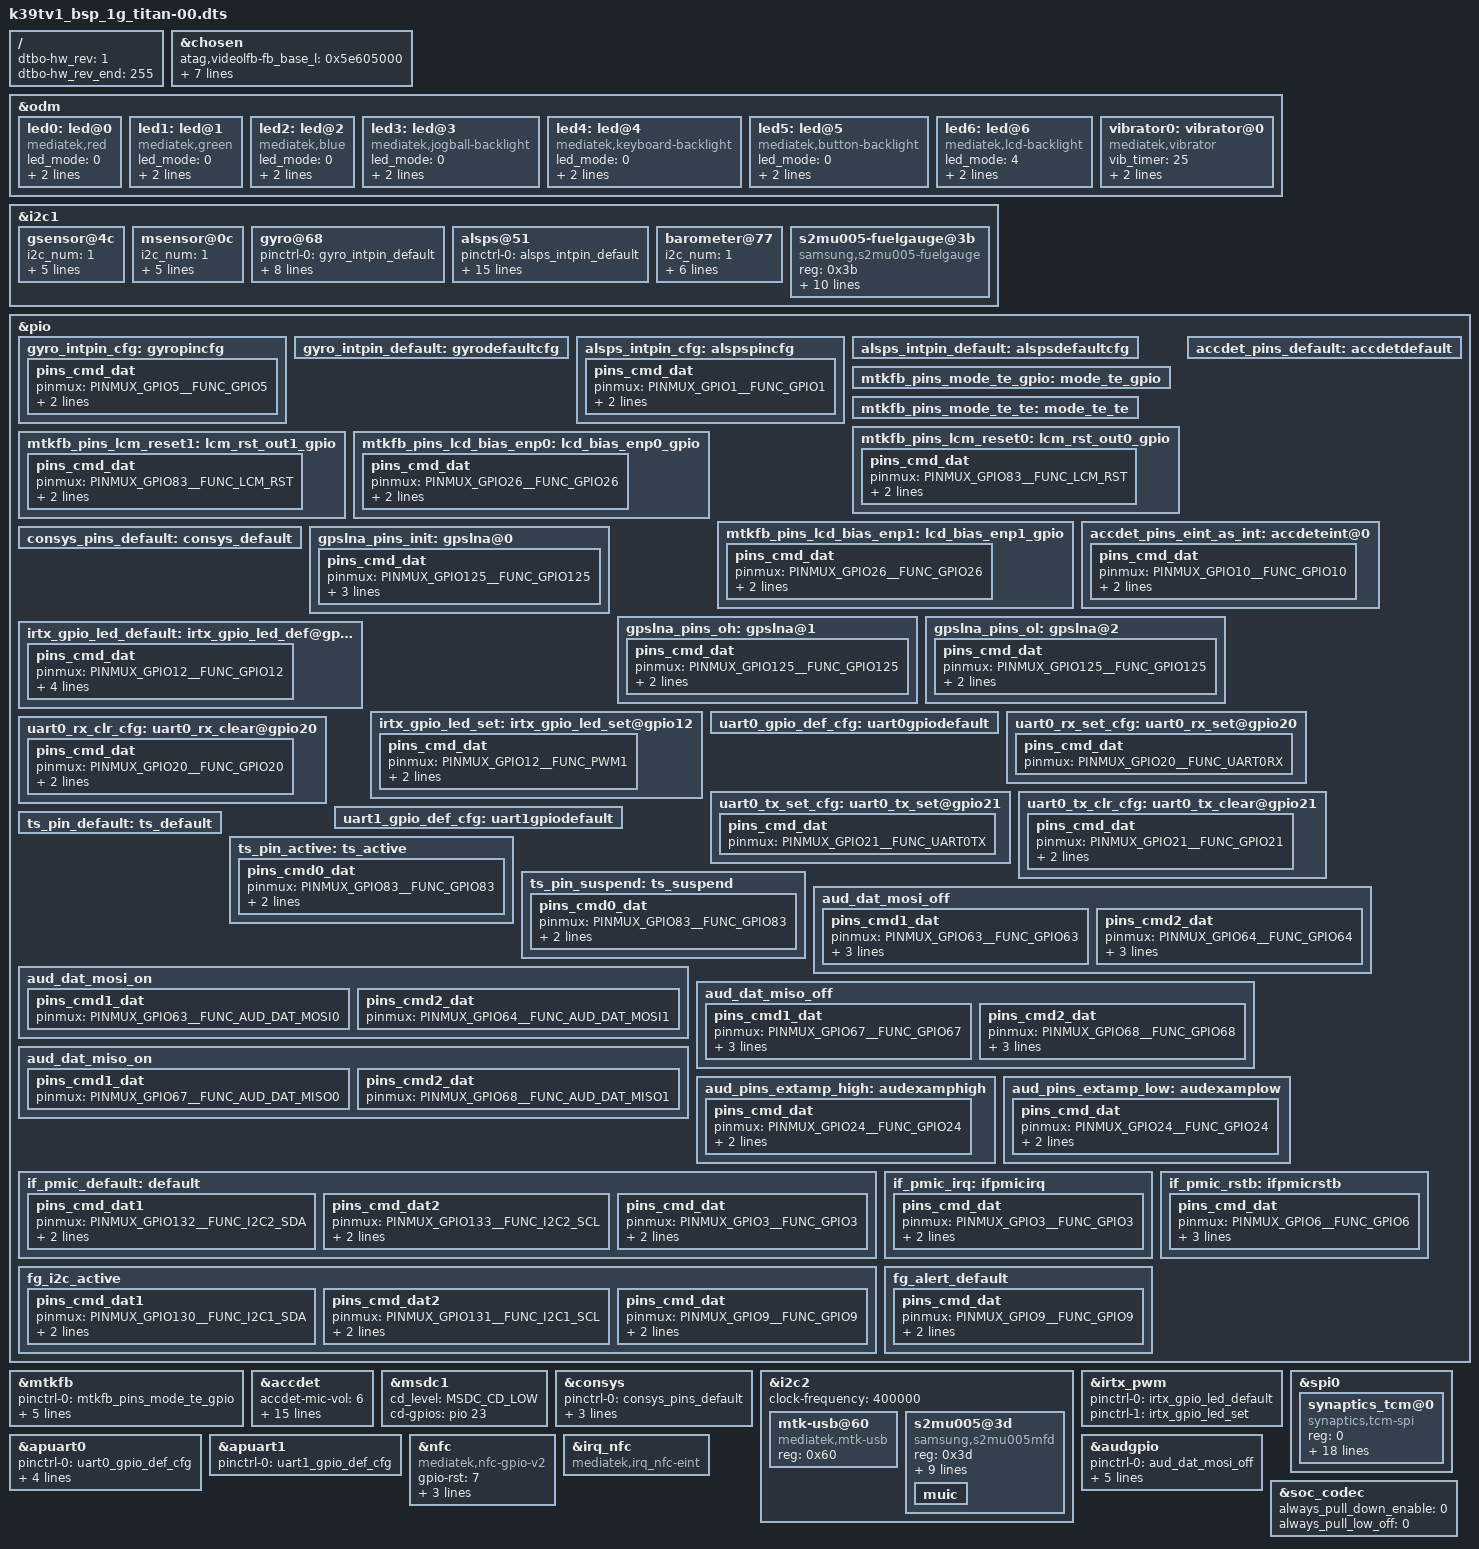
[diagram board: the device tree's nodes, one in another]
/*
 * Mediatek's MT6739 SoC device tree source
 *
 * Copyright (C) 2016 MediaTek Inc.
 *
 * This program is free software; you can redistribute it and/or modify
 * it under the terms of the GNU General Public License version 2 as
 * published by the Free Software Foundation.
 *
 * This program is distributed in the hope that it will be useful,
 * but WITHOUT ANY WARRANTY; without even the implied warranty of
 * MERCHANTABILITY or FITNESS FOR A PARTICULAR PURPOSE.
 * See http://www.gnu.org/licenses/gpl-2.0.html for more details.
 */
#include <generated/autoconf.h>
/dts-v1/;

/plugin/;
#include <dt-bindings/mmc/mt6739-msdc.h>
#include <dt-bindings/pinctrl/mt6739-pinfunc.h>

/ {
	fragment@model {
	target-path = "/";
		__overlay__ {
			dtbo-hw_rev = <1>;
			dtbo-hw_rev_end = <255>;
		};
	};
};

/* chosen */
&chosen {
	/* fpga may has no lk, we need to specify display info here */
	/* fb buffer is reserved using this dts by memory node above */

	atag,videolfb-fb_base_l = <0x5e605000>;
	atag,videolfb-fb_base_h = <0>;
	atag,videolfb-islcmfound = <1>;
	atag,videolfb-islcm_inited = <0>;
	atag,videolfb-fps= <6000>;
	atag,videolfb-vramSize= <0x017bb000>;
	atag,videolfb-lcmname= "nt35521_hd_dsi_vdo_truly_nt50358_drv";
};

&odm {
	led0:led@0 {
		compatible = "mediatek,red";
		led_mode = <0>;
		data = <1>;
		pwm_config = <0 0 0 0 0>;
	};
	led1:led@1 {
		compatible = "mediatek,green";
		led_mode = <0>;
		data = <1>;
		pwm_config = <0 0 0 0 0>;
	};
	led2:led@2 {
		compatible = "mediatek,blue";
		led_mode = <0>;
		data = <1>;
		pwm_config = <0 0 0 0 0>;
	};
	led3:led@3 {
		compatible = "mediatek,jogball-backlight";
		led_mode = <0>;
		data = <1>;
		pwm_config = <0 0 0 0 0>;
	};
	led4:led@4 {
		compatible = "mediatek,keyboard-backlight";
		led_mode = <0>;
		data = <1>;
		pwm_config = <0 0 0 0 0>;
	};
	led5:led@5 {
		compatible = "mediatek,button-backlight";
		led_mode = <0>;
		data = <1>;
		pwm_config = <0 0 0 0 0>;
	};
	led6:led@6 {
		compatible = "mediatek,lcd-backlight";
		led_mode = <4>;
		data = <1>;
		pwm_config = <0 2 0 0 0>;
	};
	vibrator0:vibrator@0 {
		compatible = "mediatek,vibrator";
		vib_timer = <25>;
		vib_limit = <9>;
		vib_vol= <9>;
	};
};

&i2c1 {
/*  start sensor */
	gsensor@4c {
		i2c_num	= <1>;
		direction = <6>;
		power_id = <0xffff>;
		power_vol = <0>;
		firlen = <16>;
		is_batch_supported = <1>;
	};

	msensor@0c {
		i2c_num = <1>;
		i2c_addr = <0x0d 0 0 0>;
		direction = <8>;
		power_id = <0xffff>;
		power_vol = <0>;
		is_batch_supported = <0>;
	};

	gyro@68 {
		pinctrl-names = "pin_default", "pin_cfg";
		pinctrl-0 = <&gyro_intpin_default>;
		pinctrl-1 = <&gyro_intpin_cfg>;
		i2c_num = <1>;
		i2c_addr = <0x68 0 0 0>;
		direction = <5>;
		power_id = <0xffff>;
		power_vol = <0>;
		firlen = <0>;
		is_batch_supported = <0>;
	};

	alsps@51 {
		pinctrl-names = "pin_default", "pin_cfg";
		pinctrl-0 = <&alsps_intpin_default>;
		pinctrl-1 = <&alsps_intpin_cfg>;
		status = "okay";
		/* customization */
		i2c_num = <1>;
		i2c_addr = <0x51 0 0 0>;
		polling_mode_ps = <0>;
		polling_mode_als = <1>;
		power_id = <0xffff>;
		power_vol = <0>;
		als_level = <0 328 861 1377 3125 7721 7767 12621 23062 28430
				33274 47116 57694 57694 65535>;
		als_value = <0 133 304 502 1004 2005 3058 5005 8008 10010
				12000 16000 20000 20000 20000 20000>;
		ps_threshold_high = <26>;
		ps_threshold_low = <21>;
		is_batch_supported_ps = <0>;
		is_batch_supported_als = <0>;
	};

	barometer@77 {
		i2c_num = <1>;
		i2c_addr = <0x77 0 0 0>;
		direction = <0>;
		power_id = <0xffff>;
		power_vol = <0>;
		firlen = <32>;
		is_batch_supported = <0>;
	};
/* end sensor */
};

/* sensor gpio standization */
&pio {

	gyro_intpin_cfg: gyropincfg {

	    pins_cmd_dat {
			pinmux = <PINMUX_GPIO5__FUNC_GPIO5>;
			slew-rate = <0>;
			bias-pull-down = <00>;
		};
	};

	gyro_intpin_default: gyrodefaultcfg {

	};
};

&pio {
	alsps_intpin_cfg: alspspincfg {

		pins_cmd_dat {
			pinmux = <PINMUX_GPIO1__FUNC_GPIO1>;
			slew-rate = <0>;
			bias-pull-up = <MTK_PUPD_SET_R1R0_01>;
		};
	};

	alsps_intpin_default: alspsdefaultcfg {

	};
};

/* sensor end */

/* DISPSYS GPIO standardization */
&pio {
	mtkfb_pins_mode_te_gpio: mode_te_gpio {
	};

	mtkfb_pins_mode_te_te: mode_te_te {
	};

	mtkfb_pins_lcm_reset0: lcm_rst_out0_gpio {
		pins_cmd_dat {
			pinmux = <PINMUX_GPIO83__FUNC_LCM_RST>;
			slew-rate = <1>;
			output-low;
		};
	};

	mtkfb_pins_lcm_reset1: lcm_rst_out1_gpio {
		pins_cmd_dat {
			pinmux = <PINMUX_GPIO83__FUNC_LCM_RST>;
			slew-rate = <1>;
			output-high;
		};
	};

	mtkfb_pins_lcd_bias_enp0: lcd_bias_enp0_gpio {
		pins_cmd_dat {
			pinmux = <PINMUX_GPIO26__FUNC_GPIO26>;
			slew-rate = <1>;
			output-low;
		};
	};
	mtkfb_pins_lcd_bias_enp1: lcd_bias_enp1_gpio {
		pins_cmd_dat {
			pinmux = <PINMUX_GPIO26__FUNC_GPIO26>;
			slew-rate = <1>;
			output-high;
		};
	};

};

&mtkfb {
	pinctrl-names = "mode_te_gpio", "mode_te_te", "lcm_rst_out0_gpio",
		"lcm_rst_out1_gpio", "lcd_bias_enp0_gpio", "lcd_bias_enp1_gpio";
	pinctrl-0 = <&mtkfb_pins_mode_te_gpio>;
	pinctrl-1 = <&mtkfb_pins_mode_te_te>;
	pinctrl-2 = <&mtkfb_pins_lcm_reset0>;
	pinctrl-3 = <&mtkfb_pins_lcm_reset1>;
	pinctrl-4 = <&mtkfb_pins_lcd_bias_enp0>;
	pinctrl-5 = <&mtkfb_pins_lcd_bias_enp1>;
	status = "okay";
};
/* DISPSYS GPIO standardization end */


/* accdet start */
&accdet {
	/* accdet micbias voltage: 0x07,2.7v;0x05,2.5v;0x02,1.9v */
	accdet-mic-vol = <6>;
	headset-mode-setting = <0x500 0x500 1 0x1f0 0x800 0x800 0x20 0x44>;
	accdet-plugout-debounce = <1>;
	/*1:ACC mode, 2:low cost without in bias, 6:low cost with in bias*/
	accdet-mic-mode = <2>;
/* eint_level_trigger: 8,LEVEL_LOW(default);4,LEVEL_HIGH;others,LEVEL_LOW */
	headset-eint-level-pol = <8>;
	/*0--MD_MAX--UP_MAX--DW_MAX*/
	headset-three-key-threshold = <0 80 220 400>;
	headset-three-key-threshold-CDD = <0 121 192 600>;
	/*0--MD_MAX--VOICE_MAX--UP_MAX--DW_MAX*/
	headset-four-key-threshold = <0 58 121 192 400>;

	moisture-plug-in-threshold = <0 700 800>;
	pinctrl-names = "default", "state_eint_as_int";
	pinctrl-0 = <&accdet_pins_default>;
	pinctrl-1 = <&accdet_pins_eint_as_int>;
	interrupt-parent = <&pio>;
	interrupts = <10 0x2008>;
	deb-gpios = <&pio 10 0>;
	debounce = <512000>;
	status = "okay";
};

&pio {
	accdet_pins_default: accdetdefault {
	};
	accdet_pins_eint_as_int: accdeteint@0 {
		pins_cmd_dat {
			pinmux = <PINMUX_GPIO10__FUNC_GPIO10>;
			slew-rate = <0>;
			bias-disable;
		};
	};
};
/* accdet end */

/* MSDC1 */
&msdc1 {
	cd_level = /bits/ 8 <MSDC_CD_LOW>;
	cd-gpios = <&pio 23 0>;
};
/* MSDC1 */

/* CONSYS GPIO standardization */
&pio {
	consys_pins_default: consys_default {
	};
	gpslna_pins_init: gpslna@0 {
		pins_cmd_dat {
			pinmux = <PINMUX_GPIO125__FUNC_GPIO125>;
			slew-rate = <0>;
			bias-disable;
			output-low;
		};
	};
	gpslna_pins_oh: gpslna@1 {
		pins_cmd_dat {
			pinmux = <PINMUX_GPIO125__FUNC_GPIO125>;
			slew-rate = <1>;
			output-high;
		};
	};
	gpslna_pins_ol: gpslna@2 {
		pins_cmd_dat {
			pinmux = <PINMUX_GPIO125__FUNC_GPIO125>;
			slew-rate = <1>;
			output-low;
		};
	};
};
&consys {
	pinctrl-names = "default", "gps_lna_state_init",
			"gps_lna_state_oh", "gps_lna_state_ol";
	pinctrl-0 = <&consys_pins_default>;
	pinctrl-1 = <&gpslna_pins_init>;
	pinctrl-2 = <&gpslna_pins_oh>;
	pinctrl-3 = <&gpslna_pins_ol>;
	status = "okay";
};
&i2c2 {
	#address-cells = <1>;
	#size-cells = <0>;
	clock-frequency = <400000>;

	mtk-usb@60 {
		compatible = "mediatek,mtk-usb";
		reg = <0x60>;
		status = "okay";
	};
};

/* IRTX GPIO Start */
&irtx_pwm {
	pinctrl-names = "irtx_gpio_led_default", "irtx_gpio_led_set";
	pinctrl-0 = <&irtx_gpio_led_default>;
	pinctrl-1 = <&irtx_gpio_led_set>;
	status = "okay";
};
&pio {
	/* IRTX GPIO Settings -Start */
	/* default: GPIO0, output, high */
	irtx_gpio_led_default:irtx_gpio_led_def@gpio12 {
		pins_cmd_dat {
			pinmux = <PINMUX_GPIO12__FUNC_GPIO12>;
			slew-rate = <1>;
			bias-disable;
			output-low;
			input-schmitt-enable = <0>;
		};
	};

	irtx_gpio_led_set:irtx_gpio_led_set@gpio12 {
		pins_cmd_dat {
			pinmux = <PINMUX_GPIO12__FUNC_PWM1>;
			slew-rate = <1>;
			output-high;
		};
	};
}; /* IRTX GPIO Settings -End */

/* UART GPIO */
&apuart0 {
	pinctrl-names = "uart0_gpio_default",
			"uart0_rx_set",
			"uart0_rx_clear",
			"uart0_tx_set",
			"uart0_tx_clear";
	pinctrl-0 = <&uart0_gpio_def_cfg>;
	pinctrl-1 = <&uart0_rx_set_cfg>;
	pinctrl-2 = <&uart0_rx_clr_cfg>;
	pinctrl-3 = <&uart0_tx_set_cfg>;
	pinctrl-4 = <&uart0_tx_clr_cfg>;
	status = "okay";
};

&apuart1 {
	pinctrl-names = "uart1_gpio_default";
	pinctrl-0 = <&uart1_gpio_def_cfg>;
	status = "okay";
};

&pio {
	/* UART GPIO Settings - Start */
	/* UART0: rx set, rx clear, tx clear, tx clear*/
	uart0_gpio_def_cfg:uart0gpiodefault {

	};
	uart0_rx_set_cfg:uart0_rx_set@gpio20 {
		pins_cmd_dat {
			pinmux = <PINMUX_GPIO20__FUNC_UART0RX>;
		};
	};
	uart0_rx_clr_cfg:uart0_rx_clear@gpio20 {
		pins_cmd_dat {
			pinmux = <PINMUX_GPIO20__FUNC_GPIO20>;
			slew-rate = <1>;
			output-high;
		};
	};
	uart0_tx_set_cfg:uart0_tx_set@gpio21 {
		pins_cmd_dat {
			pinmux = <PINMUX_GPIO21__FUNC_UART0TX>;
		};
	};
	uart0_tx_clr_cfg:uart0_tx_clear@gpio21 {
		pins_cmd_dat {
			pinmux = <PINMUX_GPIO21__FUNC_GPIO21>;
			slew-rate = <1>;
			output-high;
		};
	};
	/* UART1: rx set, rx clear, tx clear, tx clear*/
	uart1_gpio_def_cfg:uart1gpiodefault {

	};
};/* UART GPIO end */

/* TOUCH start */
&spi0 {
	status = "okay";

	#address-cells = <1>;
	#size-cells = <0>;

	synaptics_tcm@0 {
		compatible = "synaptics,tcm-spi";
		reg = <0>;
		spi-max-frequency = <5000000>;
		interrupt-parent = <&pio>;
		interrupts = <0 0x2008>;
		/* vdd-supply = <&pm8994_lvs2>; */
		/* avdd-supply = <&pm8994_l22>; */
		pinctrl-names = "pmx_ts_active", "pmx_ts_suspend";
		pinctrl-0 = <&ts_pin_active>;
		pinctrl-1 = <&ts_pin_suspend>;
		synaptics,bus-reg-name = "vdd";
		synaptics,pwr-reg-name = "avdd";
		/* IRQF_ONESHOT | IRQF_TRIGGER_LOW */
		synaptics,irq-gpio = <&pio 0 0x2008>;
		synaptics,irq-on-state = <0>;
		synaptics,reset-on-state = <0>;
		synaptics,reset-active-ms = <20>;
		synaptics,reset-delay-ms = <200>;
		synaptics,power-delay-ms = <200>;
		synaptics,spi-mode = <0>;
		synaptics,byte-delay-us = <0>;
		synaptics,block-delay-us = <0>;
		synaptics,ubl-max-freq = <5000000>;
		synaptics,ubl-byte-delay-us = <20>;
		/* tp-io reset is only used for specific tddi devices */
		/* synaptics,tpio-reset-gpio = <&msm_gpio 102 0>; */
	};
};

/* touch gpio start */
&pio {
	ts_pin_default: ts_default {
	};

	ts_pin_active: ts_active {
		pins_cmd0_dat {
			pinmux = <PINMUX_GPIO83__FUNC_GPIO83>;
			slew-rate = <1>;
			output-high;
		};
	};

	ts_pin_suspend: ts_suspend {
		pins_cmd0_dat {
			pinmux = <PINMUX_GPIO83__FUNC_GPIO83>;
			slew-rate = <1>;
			output-low;
		};
	};
};
/* touch gpio end */

/* TOUCH end */

/* NFC start */
&nfc {
	compatible = "mediatek,nfc-gpio-v2";
	gpio-rst = <7>;
	gpio-rst-std = <&pio 7 0x0>;
	gpio-irq = <14>;
	gpio-irq-std = <&pio 14 0x0>;
};

&irq_nfc {
	compatible = "mediatek,irq_nfc-eint";
};
/* NFC end */

/* AUDIO GPIO standardization */
&audgpio {
	pinctrl-names = "aud_dat_mosi_off",
			"aud_dat_mosi_on",
			"aud_dat_miso_off",
			"aud_dat_miso_on",
			"extamp-pullhigh",
			"extamp-pulllow";
	pinctrl-0 = <&aud_dat_mosi_off>;
	pinctrl-1 = <&aud_dat_mosi_on>;
	pinctrl-2 = <&aud_dat_miso_off>;
	pinctrl-3 = <&aud_dat_miso_on>;
	pinctrl-4 = <&aud_pins_extamp_high>;
	pinctrl-5 = <&aud_pins_extamp_low>;
	status = "okay";
};

&pio {
	aud_dat_mosi_off: aud_dat_mosi_off {
		pins_cmd1_dat {
			pinmux = <PINMUX_GPIO63__FUNC_GPIO63>;
			input-enable;
			slew-rate = <0>;
			bias-disable;
		};
		pins_cmd2_dat {
			pinmux = <PINMUX_GPIO64__FUNC_GPIO64>;
			input-enable;
			slew-rate = <0>;
			bias-disable;
		};
	};

	aud_dat_mosi_on: aud_dat_mosi_on {
		pins_cmd1_dat {
			pinmux = <PINMUX_GPIO63__FUNC_AUD_DAT_MOSI0>;
		};
		pins_cmd2_dat {
			pinmux = <PINMUX_GPIO64__FUNC_AUD_DAT_MOSI1>;
		};
	};

	aud_dat_miso_off: aud_dat_miso_off {
		pins_cmd1_dat {
			pinmux = <PINMUX_GPIO67__FUNC_GPIO67>;
			input-enable;
			slew-rate = <0>;
			bias-disable;
		};
		pins_cmd2_dat {
			pinmux = <PINMUX_GPIO68__FUNC_GPIO68>;
			input-enable;
			slew-rate = <0>;
			bias-disable;
		};
	};

	aud_dat_miso_on: aud_dat_miso_on {
		pins_cmd1_dat {
			pinmux = <PINMUX_GPIO67__FUNC_AUD_DAT_MISO0>;
		};
		pins_cmd2_dat {
			pinmux = <PINMUX_GPIO68__FUNC_AUD_DAT_MISO1>;
		};
	};
	aud_pins_extamp_high: audexamphigh {
		pins_cmd_dat {
			pinmux = <PINMUX_GPIO24__FUNC_GPIO24>;
			slew-rate = <1>;
			output-high;
		};
	};

	aud_pins_extamp_low: audexamplow {
		pins_cmd_dat {
			pinmux = <PINMUX_GPIO24__FUNC_GPIO24>;
			slew-rate = <1>;
			output-low;
		};
	};

};
&soc_codec {
	always_pull_down_enable = <0>; /* select 1: enable, 0: disable */
	always_pull_low_off = <0>; /* select 1: enable, 0: disable */
};
/* AUDIO end */

/* IF-PMIC configurations */
&i2c2 {

	s2mu005@3d {
		compatible = "samsung,s2mu005mfd";
		reg = <0x3d>;
		interrupt-parent = <&pio>;
		/*interrupts = <3 0x2008>;*/
		/* interrupts = <3 IRQ_TYPE_EDGE_FALLING>;*/
		interrupts = <3 0x2008>;

		pinctrl-names = "default", "ifpmicirq", "ifpmicrstb";
		pinctrl-0 = <&if_pmic_default &if_pmic_irq &if_pmic_rstb>;
		pinctrl-1 = <&if_pmic_irq>;
		pinctrl-2 = <&if_pmic_rstb>;
		s2mu005,wakeup;
		s2mu005,irq-gpio = <&pio 3 0>;
		debounce = <0 0>;
		status = "okay";

		muic {
			status = "okay";
		};
	};
};

&pio {
	if_pmic_default: default {
		/* Setting gpio mode to i2c */
		pins_cmd_dat1 {
			pinmux = <PINMUX_GPIO132__FUNC_I2C2_SDA>;
			slew-rate = <0>;
			bias-pull-down = <00>;
		};
		pins_cmd_dat2 {
			pinmux = <PINMUX_GPIO133__FUNC_I2C2_SCL>;
			slew-rate = <0>;
			bias-pull-down = <00>;
		};
		pins_cmd_dat {
			pinmux = <PINMUX_GPIO3__FUNC_GPIO3>;
			slew-rate = <0>;
			bias-pull-down = <00>;
		};
	};

	if_pmic_irq: ifpmicirq {
		pins_cmd_dat {
			pinmux = <PINMUX_GPIO3__FUNC_GPIO3>;
			slew-rate = <0>;
			bias-pull-down = <00>;
		};
	};

	if_pmic_rstb: ifpmicrstb {
		pins_cmd_dat {
			pinmux = <PINMUX_GPIO6__FUNC_GPIO6>;
			slew-rate = <1>;
			output-high;
			bias-pull-down = <00>;
		};
	};
};
/* IF-PMIC end */

/* FUELGAUGE configurations */
&i2c1 {
	s2mu005-fuelgauge@3b {
		compatible = "samsung,s2mu005-fuelgauge";
		reg = <0x3b>;
		interrupt-parent = <&pio>;
		pinctrl-names = "default";
		pinctrl-0 = <&fg_i2c_active &fg_alert_default>;
		fuelgauge,irqf = "IRQF_TRIGGER_FALLING + IRQF_ONESHOT + IRQF_NO_SUSPEND";
		fuelgauge,fuel_int = <&pio 9 0>;
		fuelgauge,fuel_alert_soc = <1>;
		fuelgauge,capacity_max = <1000>;
		fuelgauge,capacity_max_margin = <70>;
		fuelgauge,capacity_min = <0>;
		fuelgauge,capacity_calculation_type = <0x1F>;
	};
};

&pio {
	fg_i2c_active: fg_i2c_active {
		pins_cmd_dat1 {
			pinmux = <PINMUX_GPIO130__FUNC_I2C1_SDA>;	/*fuelgauge sda pin*/
			slew-rate = <0>;
			bias-pull-down = <00>;
		};
		pins_cmd_dat2 {
			pinmux = <PINMUX_GPIO131__FUNC_I2C1_SCL>;	/*fuelgauge scl pin*/
			slew-rate = <0>;
			bias-pull-down = <00>;
		};
		pins_cmd_dat {
			pinmux = <PINMUX_GPIO9__FUNC_GPIO9>;
			slew-rate = <0>;
			input-enable;
		};
	};

	fg_alert_default: fg_alert_default {
		pins_cmd_dat {
			pinmux = <PINMUX_GPIO9__FUNC_GPIO9>;
			slew-rate = <0>;
			input-enable;
		};
	};
};
/* FUELGAUGE end */

#include "battery_data_a1core_common.dtsi"
#include "cust_k39tv1_bsp_1g_titan-rev00-gpio.dtsi"
#include "cust_mt6739_camera_a01_core-rev00.dtsi"
/*End of this file, DO NOT ADD ANYTHING HERE*/
